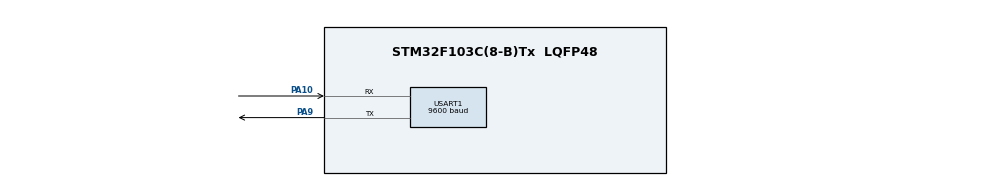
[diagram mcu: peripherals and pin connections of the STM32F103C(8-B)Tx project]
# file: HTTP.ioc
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Mcu.Family=STM32F1
RCC.APB2Freq_Value=8000000
PD1-OSC_OUT.Mode=HSE-External-Clock-Source
PA10.Mode=Asynchronous
PA14.Mode=Serial_Wire
USART1.BaudRate=9600
PA13.Mode=Serial_Wire
Mcu.Name=STM32F103C(8-B)Tx
PD0-OSC_IN.Signal=RCC_OSC_IN
Mcu.Package=LQFP48
RCC.SYSCLKSource=RCC_SYSCLKSOURCE_PLLCLK
ProjectManager.StackSize=0x400
PD1-OSC_OUT.Signal=RCC_OSC_OUT
PA13.Signal=SYS_JTMS-SWDIO
USART1.VirtualMode=VM_ASYNC
PA9.Mode=Asynchronous
PA10.Signal=USART1_RX
PA14.Signal=SYS_JTCK-SWCLK
ProjectManager.HeapSize=0x200
ProjectManager.TargetToolchain=MDK-ARM V5.27
NVIC.PriorityGroup=NVIC_PRIORITYGROUP_4
PA9.Signal=USART1_TX
NVIC.USART1_IRQn=true\:1\:0\:true\:false\:true\:true\:true
RCC.APB1Freq_Value=8000000
PD0-OSC_IN.Mode=HSE-External-Clock-Source
board=custom

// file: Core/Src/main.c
/* USER CODE BEGIN Header */
/**
  ******************************************************************************
  * @file           : main.c
  * @brief          : Main program body
  ******************************************************************************
  * @attention
  *
  * <h2><center>&copy; Copyright (c) 2021 STMicroelectronics.
  * All rights reserved.</center></h2>
  *
  * This software component is licensed by ST under BSD 3-Clause license,
  * the "License"; You may not use this file except in compliance with the
  * License. You may obtain a copy of the License at:
  *                        opensource.org/licenses/BSD-3-Clause
  *
  ******************************************************************************
  */
/* USER CODE END Header */
#include "main.h"
#include "usart.h"
#include "gpio.h"

/* USER CODE BEGIN Includes */
#include "Sim800L.h"
/* USER CODE END Includes */

/* USER CODE BEGIN PV */
char Transfer_cplt2;
char Rx_Buffer2[SIMCOM_DATA_IN_MAX_SIZE];

char httpbuffer[100];
/* USER CODE END PV */

void SystemClock_Config(void);

/* USER CODE BEGIN 0 */
void HAL_UART_RxCpltCallback(UART_HandleTypeDef *huart)
{
	if (huart-> Instance == USART1) // UART hien tai la uart1 SIM
	{
		simcom_receive_data_it();
	}
}
/* USER CODE END 0 */

int main(void)
{

  /* MCU Configuration--------------------------------------------------------*/

  /* Reset of all peripherals, Initializes the Flash interface and the Systick. */
  HAL_Init();

  /* Configure the system clock */
  SystemClock_Config();

  /* Initialize all configured peripherals */
  MX_GPIO_Init();
  MX_USART1_UART_Init();
  /* USER CODE BEGIN 2 */
	TurnUart();
  /* USER CODE END 2 */

  /* Infinite loop */
  while (1)
  {

    /* USER CODE BEGIN 3 */
		if (Sim_init()==1)
			{
				if (Sim_Bearer_Configure()==1)
				{
					sprintf(httpbuffer,"api_key=RQFTOJHZ7I56EKKK&field1=70\r\n");
					if (Sim_HTTP_Post(httpbuffer)==1)
					{
						Sim_HTTPTERM();
					}
					Sim_Bearer_Dis();
				}
			}
			while(1);
  }
  /* USER CODE END 3 */
}

void SystemClock_Config(void)
{
  RCC_OscInitTypeDef RCC_OscInitStruct = {0};
  RCC_ClkInitTypeDef RCC_ClkInitStruct = {0};

  /** Initializes the RCC Oscillators according to the specified parameters
  * in the RCC_OscInitTypeDef structure.
  */
  RCC_OscInitStruct.OscillatorType = RCC_OSCILLATORTYPE_HSI;
  RCC_OscInitStruct.HSIState = RCC_HSI_ON;
  RCC_OscInitStruct.HSICalibrationValue = RCC_HSICALIBRATION_DEFAULT;
  RCC_OscInitStruct.PLL.PLLState = RCC_PLL_ON;
  RCC_OscInitStruct.PLL.PLLSource = RCC_PLLSOURCE_HSI_DIV2;
  RCC_OscInitStruct.PLL.PLLMUL = RCC_PLL_MUL2;
  if (HAL_RCC_OscConfig(&RCC_OscInitStruct) != HAL_OK)
  {
    Error_Handler();
  }
  /** Initializes the CPU, AHB and APB buses clocks
  */
  RCC_ClkInitStruct.ClockType = RCC_CLOCKTYPE_HCLK|RCC_CLOCKTYPE_SYSCLK
                              |RCC_CLOCKTYPE_PCLK1|RCC_CLOCKTYPE_PCLK2;
  RCC_ClkInitStruct.SYSCLKSource = RCC_SYSCLKSOURCE_PLLCLK;
  RCC_ClkInitStruct.AHBCLKDivider = RCC_SYSCLK_DIV1;
  RCC_ClkInitStruct.APB1CLKDivider = RCC_HCLK_DIV1;
  RCC_ClkInitStruct.APB2CLKDivider = RCC_HCLK_DIV1;

  if (HAL_RCC_ClockConfig(&RCC_ClkInitStruct, FLASH_LATENCY_0) != HAL_OK)
  {
    Error_Handler();
  }
}

void Error_Handler(void)
{
  __disable_irq();
  while (1)
  {
  }
}

/************************ (C) COPYRIGHT STMicroelectronics *****END OF FILE****/
